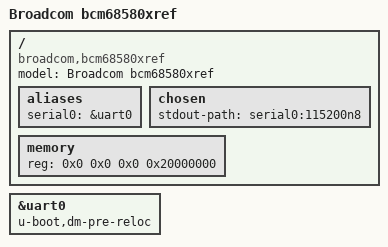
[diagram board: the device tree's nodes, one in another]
// SPDX-License-Identifier: GPL-2.0+
/*
 * Copyright (C) 2018 Philippe Reynes <philippe.reynes@softathome.com>
 */

/dts-v1/;

#include "bcm6858.dtsi"

/ {
	model = "Broadcom bcm68580xref";
	compatible = "broadcom,bcm68580xref", "brcm,bcm6858";

	aliases {
		serial0 = &uart0;
	};

	chosen {
		stdout-path = "serial0:115200n8";
	};

	memory {
		device_type = "memory";
		reg = <0x0 0x0 0x0 0x20000000>;
	};
};

&uart0 {
	u-boot,dm-pre-reloc;
	status = "okay";
};
